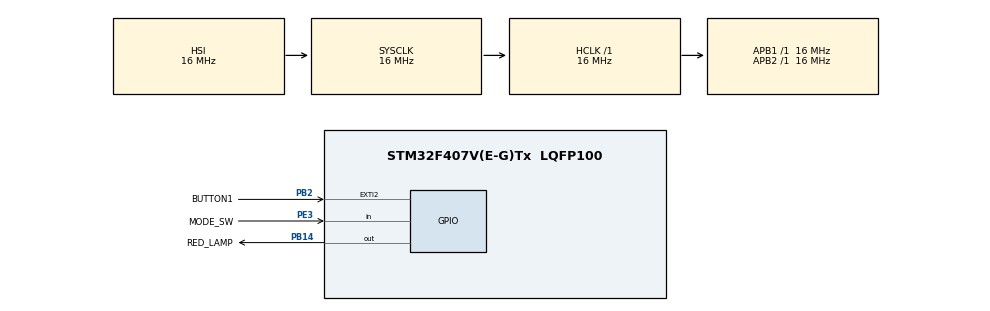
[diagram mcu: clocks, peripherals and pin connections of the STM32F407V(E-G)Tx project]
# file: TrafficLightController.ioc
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Mcu.Family=STM32F4
Mcu.Name=STM32F407V(E-G)Tx
Mcu.Package=LQFP100
NVIC.EXTI2_IRQn=true\:0\:0\:false\:false\:true\:true\:true
NVIC.PriorityGroup=NVIC_PRIORITYGROUP_4
PA13.Mode=Serial_Wire
PA13.Signal=SYS_JTMS-SWDIO
PA14.Mode=Serial_Wire
PA14.Signal=SYS_JTCK-SWCLK
PB14.GPIO_Label=RED_LAMP
PB14.Signal=GPIO_Output
PB2.GPIO_Label=BUTTON1
PB2.GPIO_ModeDefaultEXTI=GPIO_MODE_IT_FALLING
PB2.Signal=GPXTI2
PE3.GPIO_Label=MODE_SW
PE3.Signal=GPIO_Input
ProjectManager.HeapSize=0x200
ProjectManager.StackSize=0x400
ProjectManager.TargetToolchain=MDK-ARM V5
RCC.AHBFreq_Value=16000000
RCC.APB1Freq_Value=16000000
RCC.APB2Freq_Value=16000000
RCC.CortexFreq_Value=16000000
RCC.HSE_VALUE=25000000
RCC.HSI_VALUE=16000000
RCC.LSE_VALUE=32768
RCC.SYSCLKFreq_VALUE=16000000
RCC.VCOOutputFreq_Value=192000000
board=custom

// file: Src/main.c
/* USER CODE BEGIN Header */
/**
  ******************************************************************************
  * @file           : main.c
  * @brief          : Main program body
  ******************************************************************************
  * @attention
  *
  * <h2><center>&copy; Copyright (c) 2019 STMicroelectronics.
  * All rights reserved.</center></h2>
  *
  * This software component is licensed by ST under BSD 3-Clause license,
  * the "License"; You may not use this file except in compliance with the
  * License. You may obtain a copy of the License at:
  *                        opensource.org/licenses/BSD-3-Clause
  *
  ******************************************************************************
  */
/* USER CODE END Header */

#include "main.h"

/* USER CODE BEGIN Includes */
#include <stdio.h>
#include "bsp.h"
#include "timer.h"
#include "ctrler.h"
/* USER CODE END Includes */

void SystemClock_Config(void);
static void MX_GPIO_Init(void);

/* USER CODE BEGIN 0 */
int fputc(int ch, FILE *f)
{
    return ITM_SendChar(ch);
}

Event_t Event_Detect()
{
    Event_t evt = NO_EVT;

    return evt;
}
/* USER CODE END 0 */

int main(void)
{

  /* MCU Configuration--------------------------------------------------------*/

  /* Reset of all peripherals, Initializes the Flash interface and the Systick. */
  HAL_Init();

  /* Configure the system clock */
  SystemClock_Config();

  /* Initialize all configured peripherals */
  MX_GPIO_Init();

  /* Infinite loop */
  while (1)
  {

    /* USER CODE BEGIN 3 */
    Event_t evt = Event_Detect();
    uint32_t timeout_value = Ctrler_Exec(evt);
    Timeout_Config(timeout_value);
    Delay(1);
  }
  /* USER CODE END 3 */
}

void SystemClock_Config(void)
{
  RCC_OscInitTypeDef RCC_OscInitStruct = {0};
  RCC_ClkInitTypeDef RCC_ClkInitStruct = {0};

  /** Configure the main internal regulator output voltage
  */
  __HAL_RCC_PWR_CLK_ENABLE();
  __HAL_PWR_VOLTAGESCALING_CONFIG(PWR_REGULATOR_VOLTAGE_SCALE1);
  /** Initializes the CPU, AHB and APB busses clocks
  */
  RCC_OscInitStruct.OscillatorType = RCC_OSCILLATORTYPE_HSI;
  RCC_OscInitStruct.HSIState = RCC_HSI_ON;
  RCC_OscInitStruct.HSICalibrationValue = RCC_HSICALIBRATION_DEFAULT;
  RCC_OscInitStruct.PLL.PLLState = RCC_PLL_NONE;
  if (HAL_RCC_OscConfig(&RCC_OscInitStruct) != HAL_OK)
  {
    Error_Handler();
  }
  /** Initializes the CPU, AHB and APB busses clocks
  */
  RCC_ClkInitStruct.ClockType = RCC_CLOCKTYPE_HCLK|RCC_CLOCKTYPE_SYSCLK
                              |RCC_CLOCKTYPE_PCLK1|RCC_CLOCKTYPE_PCLK2;
  RCC_ClkInitStruct.SYSCLKSource = RCC_SYSCLKSOURCE_HSI;
  RCC_ClkInitStruct.AHBCLKDivider = RCC_SYSCLK_DIV1;
  RCC_ClkInitStruct.APB1CLKDivider = RCC_HCLK_DIV1;
  RCC_ClkInitStruct.APB2CLKDivider = RCC_HCLK_DIV1;

  if (HAL_RCC_ClockConfig(&RCC_ClkInitStruct, FLASH_LATENCY_0) != HAL_OK)
  {
    Error_Handler();
  }
}

static void MX_GPIO_Init(void)
{
  GPIO_InitTypeDef GPIO_InitStruct = {0};

  /* GPIO Ports Clock Enable */
  __HAL_RCC_GPIOE_CLK_ENABLE();
  __HAL_RCC_GPIOB_CLK_ENABLE();
  __HAL_RCC_GPIOA_CLK_ENABLE();

  /*Configure GPIO pin Output Level */
  HAL_GPIO_WritePin(RED_LAMP_GPIO_Port, RED_LAMP_Pin, GPIO_PIN_RESET);

  /*Configure GPIO pin : MODE_SW_Pin */
  GPIO_InitStruct.Pin = MODE_SW_Pin;
  GPIO_InitStruct.Mode = GPIO_MODE_INPUT;
  GPIO_InitStruct.Pull = GPIO_NOPULL;
  HAL_GPIO_Init(MODE_SW_GPIO_Port, &GPIO_InitStruct);

  /*Configure GPIO pin : BUTTON1_Pin */
  GPIO_InitStruct.Pin = BUTTON1_Pin;
  GPIO_InitStruct.Mode = GPIO_MODE_IT_FALLING;
  GPIO_InitStruct.Pull = GPIO_NOPULL;
  HAL_GPIO_Init(BUTTON1_GPIO_Port, &GPIO_InitStruct);

  /*Configure GPIO pin : RED_LAMP_Pin */
  GPIO_InitStruct.Pin = RED_LAMP_Pin;
  GPIO_InitStruct.Mode = GPIO_MODE_OUTPUT_PP;
  GPIO_InitStruct.Pull = GPIO_NOPULL;
  GPIO_InitStruct.Speed = GPIO_SPEED_FREQ_LOW;
  HAL_GPIO_Init(RED_LAMP_GPIO_Port, &GPIO_InitStruct);

  /* EXTI interrupt init*/
  HAL_NVIC_SetPriority(EXTI2_IRQn, 0, 0);
  HAL_NVIC_EnableIRQ(EXTI2_IRQn);

}

void Error_Handler(void)
{
}

/************************ (C) COPYRIGHT STMicroelectronics *****END OF FILE****/
